# MIK32 register map
Vendor: Mikron JSC; Series: MIK32; File version: 1.0
Registers are 32-bit, read-write, reset 0x0 unless marked. A register's access mark holds for its fields unless they carry their own. Offsets are from the block's base; [hi:lo] are bit positions; 'fields as' and 'values as' point back to an identical list.

## EPIC — Программируемый контроллер прерываний
Base 0x00050400
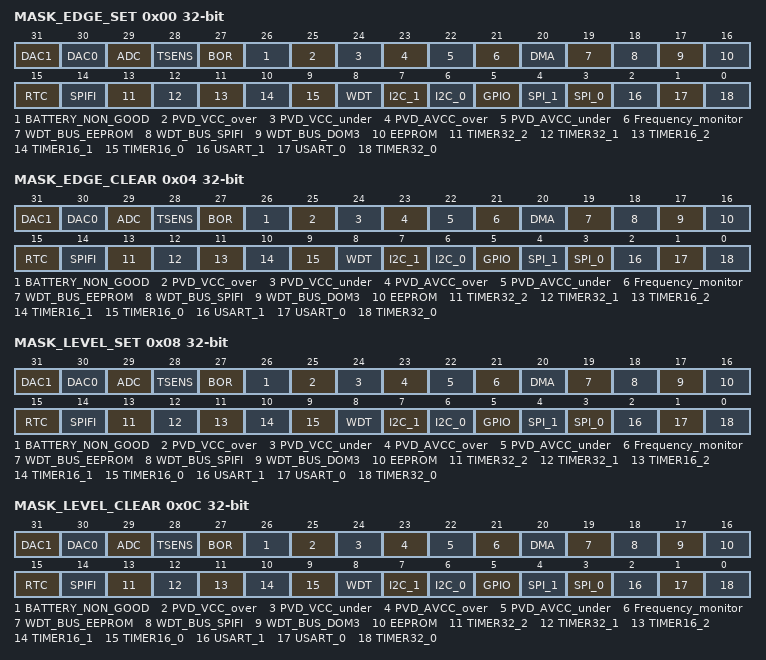
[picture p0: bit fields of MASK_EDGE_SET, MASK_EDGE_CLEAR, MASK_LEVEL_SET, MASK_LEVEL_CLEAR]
0x00 MASK_EDGE_SET write-1-sets — Установка маски прерываний по фронту. При чтении – текущее состояние масок прерываний по фронту. Запись «1» разрешает прерывание по фронту соответствующего источника прерываний.
  [all] fields
    0=Disable (Прерывание по фронту запрешено); 1=Enable (Прерывание по фронту разрешено)
  [31] DAC1 — Линия прерывания ЦАП1
  [30] DAC0 — Линия прерывания ЦАП0
  [29] ADC — Линия прерывания АЦП
  [28] TSENS — Линия прерывания монитора температуры
  [27] BOR — Линия прерывания BrouwnOut детектора
  [26] BATTERY_NON_GOOD — Линия прерывания недостаточного напряжения батареи
  [25] PVD_VCC_over — Линия прерывания монитора напряжения VCC (выше порога)
  [24] PVD_VCC_under — Линия прерывания монитора напряжения VCC (ниже порога)
  [23] PVD_AVCC_over — Линия прерывания монитора напряжения AVCC (выше порога)
  [22] PVD_AVCC_under — Линия прерывания монитора напряжения AVCC (ниже порога)
  [21] Frequency_monitor — Линия прерывания монитора частоты
  [20] DMA — Линия прерывания ПДП
  [19] WDT_BUS_EEPROM — Линия прерывания сторожевого таймера шины (EEPROM)
  [18] WDT_BUS_SPIFI — Линия прерывания сторожевого таймера шины (SPIFI)
  [17] WDT_BUS_DOM3 — Линия прерывания сторожевого таймера шины (периферийные устройства)
  [16] EEPROM — Линия прерывания EEPROM
  [15] RTC — Линия прерывания RTC
  [14] SPIFI — Линия прерывания SPIFI
  [13] TIMER32_2 — Линия прерывания TIMER32_2
  [12] TIMER32_1 — Линия прерывания TIMER32_1
  [11] TIMER16_2 — Линия прерывания TIMER16_2
  [10] TIMER16_1 — Линия прерывания TIMER16_1
  [9] TIMER16_0 — Линия прерывания TIMER16_0
  [8] WDT — Линия прерывания сторожевого таймера (WDT)
  [7] I2C_1 — Линия прерывания I2C_1
  [6] I2C_0 — Линия прерывания I2C_0
  [5] GPIO — Линия прерывания GPIO
  [4] SPI_1 — Линия прерывания SPI_1
  [3] SPI_0 — Линия прерывания SPI_0
  [2] USART_1 — Линия прерывания USART_1
  [1] USART_0 — Линия прерывания USART_0
  [0] TIMER32_0 — Линия прерывания TIMER32_0
0x04 MASK_EDGE_CLEAR write-1-clears — Сброс маски прерываний по фронту. При чтении – текущее состояние масок прерываний по фронту. Запись «1» запрещает прерывание по фронту соответствующего источника прерываний.
  fields as MASK_EDGE_SET
0x08 MASK_LEVEL_SET write-1-sets — Установка маски прерываний по уровню. При чтении – текущее состояние масок прерываний по уровню. Запись «1» разрешает прерывание по уровню соответствующего источника прерываний.
  [31] DAC1 — Линия прерывания ЦАП1
  [30] DAC0 — Линия прерывания ЦАП0
  [29] ADC — Линия прерывания АЦП
  [28] TSENS — Линия прерывания монитора температуры
  [27] BOR — Линия прерывания BrouwnOut детектора
  [26] BATTERY_NON_GOOD — Линия прерывания недостаточного напряжения батареи
  [25] PVD_VCC_over — Линия прерывания монитора напряжения VCC (выше порога)
  [24] PVD_VCC_under — Линия прерывания монитора напряжения VCC (ниже порога)
  [23] PVD_AVCC_over — Линия прерывания монитора напряжения AVCC (выше порога)
  [22] PVD_AVCC_under — Линия прерывания монитора напряжения AVCC (ниже порога)
  [21] Frequency_monitor — Линия прерывания монитора частоты
  [20] DMA — Линия прерывания ПДП
  [19] WDT_BUS_EEPROM — Линия прерывания сторожевого таймера шины (EEPROM)
  [18] WDT_BUS_SPIFI — Линия прерывания сторожевого таймера шины (SPIFI)
  [17] WDT_BUS_DOM3 — Линия прерывания сторожевого таймера шины (периферийные устройства)
  [16] EEPROM — Линия прерывания EEPROM
  [15] RTC — Линия прерывания RTC
  [14] SPIFI — Линия прерывания SPIFI
  [13] TIMER32_2 — Линия прерывания TIMER32_2
  [12] TIMER32_1 — Линия прерывания TIMER32_1
  [11] TIMER16_2 — Линия прерывания TIMER16_2
  [10] TIMER16_1 — Линия прерывания TIMER16_1
  [9] TIMER16_0 — Линия прерывания TIMER16_0
  [8] WDT — Линия прерывания сторожевого таймера (WDT)
  [7] I2C_1 — Линия прерывания I2C_1
  [6] I2C_0 — Линия прерывания I2C_0
  [5] GPIO — Линия прерывания GPIO
  [4] SPI_1 — Линия прерывания SPI_1
  [3] SPI_0 — Линия прерывания SPI_0
  [2] USART_1 — Линия прерывания USART_1
  [1] USART_0 — Линия прерывания USART_0
  [0] TIMER32_0 — Линия прерывания TIMER32_0
0x0C MASK_LEVEL_CLEAR write-1-clears — Сброс маски прерываний по уровню. При чтении – текущее состояние масок прерываний по уровню. Запись «1» запрещает прерывание по уровню соответствующего источника прерываний.
  fields as MASK_LEVEL_SET
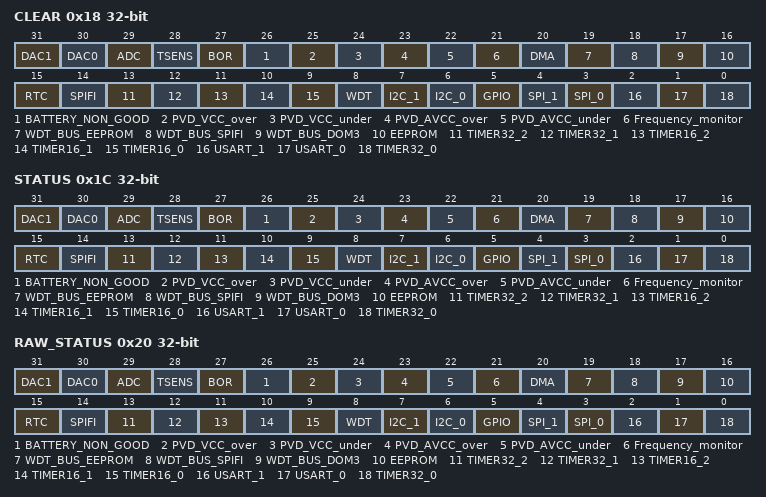
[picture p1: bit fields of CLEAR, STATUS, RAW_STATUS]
0x18 CLEAR wo write-1-clears — Сброс флагов в статусе прерываний
  [31] DAC1 rw — Линия прерывания ЦАП1
  [30] DAC0 rw — Линия прерывания ЦАП0
  [29] ADC rw — Линия прерывания АЦП
  [28] TSENS rw — Линия прерывания монитора температуры
  [27] BOR rw — Линия прерывания BrouwnOut детектора
  [26] BATTERY_NON_GOOD rw — Линия прерывания недостаточного напряжения батареи
  [25] PVD_VCC_over rw — Линия прерывания монитора напряжения VCC (выше порога)
  [24] PVD_VCC_under rw — Линия прерывания монитора напряжения VCC (ниже порога)
  [23] PVD_AVCC_over rw — Линия прерывания монитора напряжения AVCC (выше порога)
  [22] PVD_AVCC_under rw — Линия прерывания монитора напряжения AVCC (ниже порога)
  [21] Frequency_monitor rw — Линия прерывания монитора частоты
  [20] DMA rw — Линия прерывания ПДП
  [19] WDT_BUS_EEPROM rw — Линия прерывания сторожевого таймера шины (EEPROM)
  [18] WDT_BUS_SPIFI rw — Линия прерывания сторожевого таймера шины (SPIFI)
  [17] WDT_BUS_DOM3 rw — Линия прерывания сторожевого таймера шины (периферийные устройства)
  [16] EEPROM rw — Линия прерывания EEPROM
  [15] RTC rw — Линия прерывания RTC
  [14] SPIFI rw — Линия прерывания SPIFI
  [13] TIMER32_2 rw — Линия прерывания TIMER32_2
  [12] TIMER32_1 rw — Линия прерывания TIMER32_1
  [11] TIMER16_2 rw — Линия прерывания TIMER16_2
  [10] TIMER16_1 rw — Линия прерывания TIMER16_1
  [9] TIMER16_0 rw — Линия прерывания TIMER16_0
  [8] WDT rw — Линия прерывания сторожевого таймера (WDT)
  [7] I2C_1 rw — Линия прерывания I2C_1
  [6] I2C_0 rw — Линия прерывания I2C_0
  [5] GPIO rw — Линия прерывания GPIO
  [4] SPI_1 rw — Линия прерывания SPI_1
  [3] SPI_0 rw — Линия прерывания SPI_0
  [2] USART_1 rw — Линия прерывания USART_1
  [1] USART_0 rw — Линия прерывания USART_0
  [0] TIMER32_0 rw — Линия прерывания TIMER32_0
0x1C STATUS ro — Статус прерываний
  fields as MASK_LEVEL_SET
0x20 RAW_STATUS ro reset not defined — Текущее состоянии линий прерываний
  fields as MASK_LEVEL_SET
